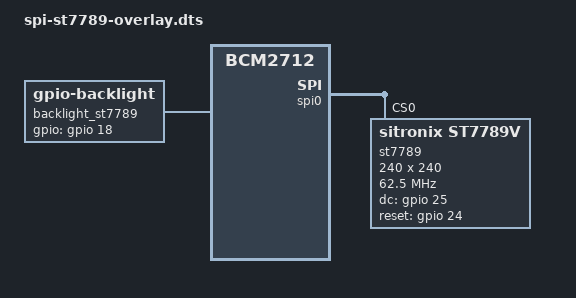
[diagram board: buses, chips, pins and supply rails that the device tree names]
// Raspberry Pi 5 - ST7789 SPI Display Overlays
// Device Tree Overlays for ST7789 based displays
// Copyright (C) 2025 The Android Open Source Project

/dts-v1/;
/plugin/;

// ============================================================================
// ST7789 240x240 Display (Pimoroni, Waveshare, etc.)
// ============================================================================
/ {
    compatible = "brcm,bcm2712";
    
    fragment@0 {
        target = <&spi0>;
        __overlay__ {
            status = "okay";
            #address-cells = <1>;
            #size-cells = <0>;
            
            st7789: st7789@0 {
                compatible = "sitronix,st7789v";
                reg = <0>;
                spi-max-frequency = <62500000>;
                
                dc-gpios = <&gpio 25 0>;
                reset-gpios = <&gpio 24 0>;
                
                width = <240>;
                height = <240>;
                buswidth = <8>;
                fps = <60>;
            };
        };
    };
    
    fragment@1 {
        target = <&gpio>;
        __overlay__ {
            st7789_pins: st7789_pins {
                brcm,pins = <24 25 18>;
                brcm,function = <1 1 1>;
            };
        };
    };
    
    fragment@2 {
        target-path = "/";
        __overlay__ {
            backlight_st7789: backlight {
                compatible = "gpio-backlight";
                gpios = <&gpio 18 0>;
                default-on;
            };
        };
    };
};
